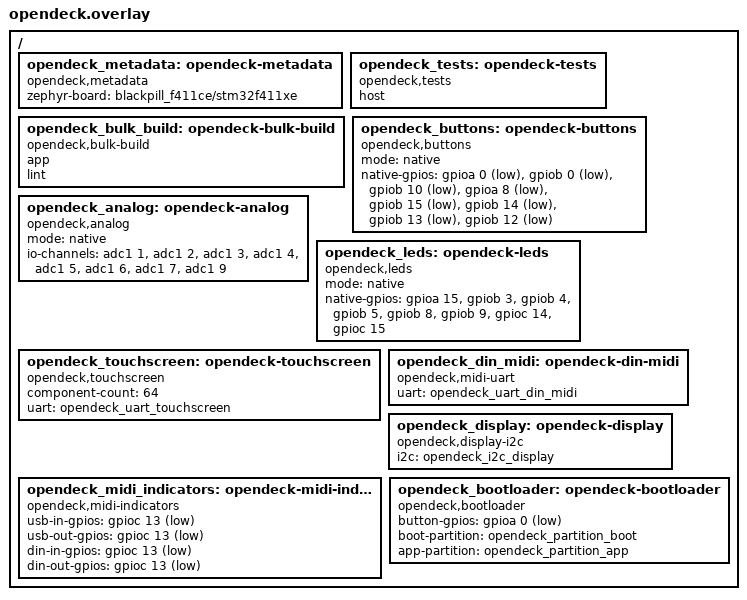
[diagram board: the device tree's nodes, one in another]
/ {
    opendeck_metadata: opendeck-metadata {
        compatible = "opendeck,metadata";
        zephyr-board = "blackpill_f411ce/stm32f411xe";
    };

    opendeck_tests: opendeck-tests {
        compatible = "opendeck,tests";
        host;
    };

    opendeck_bulk_build: opendeck-bulk-build {
        compatible = "opendeck,bulk-build";
        app;
        lint;
    };

    opendeck_buttons: opendeck-buttons {
        compatible = "opendeck,buttons";
        mode = "native";
        native-gpios =
            <&gpioa 0 (GPIO_PULL_UP | GPIO_ACTIVE_LOW)>,
            <&gpiob 0 (GPIO_PULL_UP | GPIO_ACTIVE_LOW)>,
            <&gpiob 10 (GPIO_PULL_UP | GPIO_ACTIVE_LOW)>,
            <&gpioa 8 (GPIO_PULL_UP | GPIO_ACTIVE_LOW)>,
            <&gpiob 15 (GPIO_PULL_UP | GPIO_ACTIVE_LOW)>,
            <&gpiob 14 (GPIO_PULL_UP | GPIO_ACTIVE_LOW)>,
            <&gpiob 13 (GPIO_PULL_UP | GPIO_ACTIVE_LOW)>,
            <&gpiob 12 (GPIO_PULL_UP | GPIO_ACTIVE_LOW)>;
    };

    opendeck_analog: opendeck-analog {
        compatible = "opendeck,analog";
        mode = "native";
        io-channels =
            <&adc1 1>,
            <&adc1 2>,
            <&adc1 3>,
            <&adc1 4>,
            <&adc1 5>,
            <&adc1 6>,
            <&adc1 7>,
            <&adc1 9>;
    };

    opendeck_leds: opendeck-leds {
        compatible = "opendeck,leds";
        mode = "native";
        native-gpios =
            <&gpioa 15 GPIO_ACTIVE_HIGH>,
            <&gpiob 3 GPIO_ACTIVE_HIGH>,
            <&gpiob 4 GPIO_ACTIVE_HIGH>,
            <&gpiob 5 GPIO_ACTIVE_HIGH>,
            <&gpiob 8 GPIO_ACTIVE_HIGH>,
            <&gpiob 9 GPIO_ACTIVE_HIGH>,
            <&gpioc 14 GPIO_ACTIVE_HIGH>,
            <&gpioc 15 GPIO_ACTIVE_HIGH>;
    };

    opendeck_touchscreen: opendeck-touchscreen {
        compatible = "opendeck,touchscreen";
        component-count = <64>;
        uart = <&opendeck_uart_touchscreen>;
    };

    opendeck_din_midi: opendeck-din-midi {
        compatible = "opendeck,midi-uart";
        uart = <&opendeck_uart_din_midi>;
    };

    opendeck_display: opendeck-display {
        compatible = "opendeck,display-i2c";
        i2c = <&opendeck_i2c_display>;
    };

    opendeck_midi_indicators: opendeck-midi-indicators {
        compatible = "opendeck,midi-indicators";
        usb-in-gpios = <&gpioc 13 GPIO_ACTIVE_LOW>;
        usb-out-gpios = <&gpioc 13 GPIO_ACTIVE_LOW>;
        din-in-gpios = <&gpioc 13 GPIO_ACTIVE_LOW>;
        din-out-gpios = <&gpioc 13 GPIO_ACTIVE_LOW>;
    };

    opendeck_bootloader: opendeck-bootloader {
        compatible = "opendeck,bootloader";
        button-gpios = <&gpioa 0 (GPIO_PULL_UP | GPIO_ACTIVE_LOW)>;
        boot-partition = <&opendeck_partition_boot>;
        app-partition = <&opendeck_partition_app>;
    };
};
